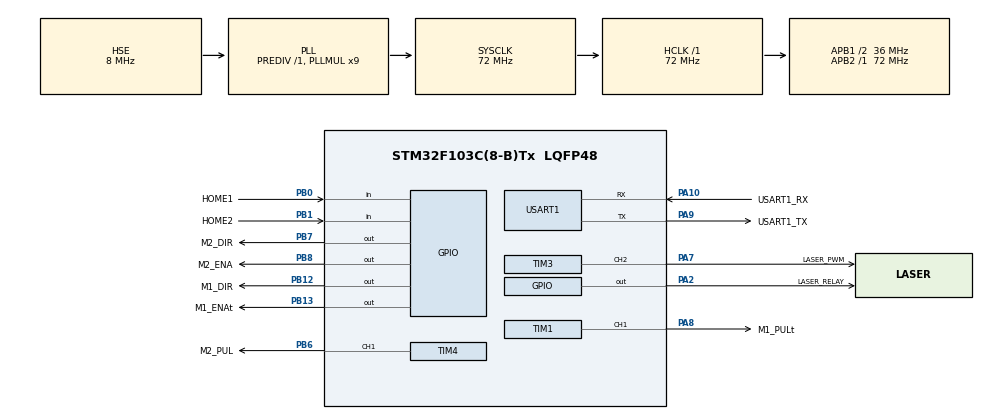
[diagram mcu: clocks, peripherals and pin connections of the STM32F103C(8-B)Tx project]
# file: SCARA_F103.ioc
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Dma.Request0=USART1_RX
Dma.Request1=USART1_TX
Dma.USART1_RX.0.Direction=DMA_PERIPH_TO_MEMORY
Dma.USART1_RX.0.Instance=DMA1_Channel5
Dma.USART1_RX.0.MemDataAlignment=DMA_MDATAALIGN_BYTE
Dma.USART1_RX.0.MemInc=DMA_MINC_ENABLE
Dma.USART1_RX.0.Mode=DMA_CIRCULAR
Dma.USART1_RX.0.PeriphDataAlignment=DMA_PDATAALIGN_BYTE
Dma.USART1_RX.0.PeriphInc=DMA_PINC_DISABLE
Dma.USART1_RX.0.Priority=DMA_PRIORITY_LOW
Dma.USART1_TX.1.Direction=DMA_MEMORY_TO_PERIPH
Dma.USART1_TX.1.Instance=DMA1_Channel4
Dma.USART1_TX.1.MemDataAlignment=DMA_MDATAALIGN_BYTE
Dma.USART1_TX.1.MemInc=DMA_MINC_ENABLE
Dma.USART1_TX.1.Mode=DMA_NORMAL
Dma.USART1_TX.1.PeriphDataAlignment=DMA_PDATAALIGN_BYTE
Dma.USART1_TX.1.PeriphInc=DMA_PINC_DISABLE
Dma.USART1_TX.1.Priority=DMA_PRIORITY_LOW
Mcu.Family=STM32F1
Mcu.Name=STM32F103C(8-B)Tx
Mcu.Package=LQFP48
NVIC.DMA1_Channel4_IRQn=true\:3\:0\:true\:false\:true\:false\:true\:true
NVIC.DMA1_Channel5_IRQn=true\:3\:0\:true\:false\:true\:false\:true\:true
NVIC.PriorityGroup=NVIC_PRIORITYGROUP_4
NVIC.TIM2_IRQn=true\:1\:0\:true\:false\:true\:true\:true\:true
NVIC.USART1_IRQn=true\:2\:0\:true\:false\:true\:false\:true\:true
PA10.GPIO_Label=USART1_RX
PA10.Mode=Asynchronous
PA10.Signal=USART1_RX
PA2.GPIO_Label=LASER_RELAY
PA2.GPIO_ModeDefaultOutputPP=GPIO_MODE_OUTPUT_PP
PA2.GPIO_PuPd=GPIO_NOPULL
PA2.GPIO_Speed=GPIO_SPEED_FREQ_LOW
PA2.PinState=GPIO_PIN_RESET
PA2.Signal=GPIO_Output
PA7.GPIO_Label=LASER_PWM
PA7.GPIO_ModeDefaultPP=GPIO_MODE_AF_PP
PA7.GPIO_Speed=GPIO_SPEED_FREQ_HIGH
PA7.Signal=S_TIM3_CH2
PA13.Mode=Serial_Wire
PA13.Signal=SYS_JTMS-SWDIO
PA14.Mode=Serial_Wire
PA14.Signal=SYS_JTCK-SWCLK
PA8.GPIO_Label=M1_PUL\t
PA8.GPIO_ModeDefaultPP=GPIO_MODE_AF_OD
PA8.GPIO_Speed=GPIO_SPEED_FREQ_HIGH
PA8.Signal=S_TIM1_CH1
PA9.GPIO_Label=USART1_TX
PA9.Mode=Asynchronous
PA9.Signal=USART1_TX
PB0.GPIO_Label=HOME1
PB0.GPIO_PuPd=GPIO_PULLUP
PB0.Signal=GPIO_Input
PB1.GPIO_Label=HOME2
PB1.GPIO_PuPd=GPIO_PULLUP
PB1.Signal=GPIO_Input
PB12.GPIO_Label=M1_DIR
PB12.GPIO_ModeDefaultOutputPP=GPIO_MODE_OUTPUT_OD
PB12.GPIO_PuPd=GPIO_NOPULL
PB12.GPIO_Speed=GPIO_SPEED_FREQ_HIGH
PB12.PinState=GPIO_PIN_SET
PB12.Signal=GPIO_Output
PB13.GPIO_Label=M1_ENA\t
PB13.GPIO_ModeDefaultOutputPP=GPIO_MODE_OUTPUT_OD
PB13.GPIO_PuPd=GPIO_NOPULL
PB13.GPIO_Speed=GPIO_SPEED_FREQ_HIGH
PB13.PinState=GPIO_PIN_SET
PB13.Signal=GPIO_Output
PB6.GPIO_Label=M2_PUL
PB6.GPIO_ModeDefaultPP=GPIO_MODE_AF_OD
PB6.GPIO_Speed=GPIO_SPEED_FREQ_HIGH
PB6.Signal=S_TIM4_CH1
PB7.GPIO_Label=M2_DIR
PB7.GPIO_ModeDefaultOutputPP=GPIO_MODE_OUTPUT_OD
PB7.GPIO_PuPd=GPIO_NOPULL
PB7.GPIO_Speed=GPIO_SPEED_FREQ_HIGH
PB7.PinState=GPIO_PIN_SET
PB7.Signal=GPIO_Output
PB8.GPIO_Label=M2_ENA
PB8.GPIO_ModeDefaultOutputPP=GPIO_MODE_OUTPUT_OD
PB8.GPIO_PuPd=GPIO_NOPULL
PB8.GPIO_Speed=GPIO_SPEED_FREQ_HIGH
PB8.PinState=GPIO_PIN_SET
PB8.Signal=GPIO_Output
PD0-OSC_IN.Mode=HSE-External-Oscillator
PD0-OSC_IN.Signal=RCC_OSC_IN
PD1-OSC_OUT.Mode=HSE-External-Oscillator
PD1-OSC_OUT.Signal=RCC_OSC_OUT
ProjectManager.HeapSize=0x200
ProjectManager.StackSize=0x400
ProjectManager.TargetToolchain=CMake
RCC.AHBFreq_Value=72000000
RCC.APB1CLKDivider=RCC_HCLK_DIV2
RCC.APB1Freq_Value=36000000
RCC.APB1TimFreq_Value=72000000
RCC.APB2Freq_Value=72000000
RCC.APB2TimFreq_Value=72000000
RCC.HCLKFreq_Value=72000000
RCC.PLLMUL=RCC_PLL_MUL9
RCC.PLLSourceVirtual=RCC_PLLSOURCE_HSE
RCC.SYSCLKFreq_VALUE=72000000
RCC.SYSCLKSource=RCC_SYSCLKSOURCE_PLLCLK
RCC.USBFreq_Value=72000000
SH.S_TIM1_CH1.0=TIM1_CH1,PWM Generation1 CH1
SH.S_TIM3_CH2.0=TIM3_CH2,PWM Generation2 CH2
SH.S_TIM4_CH1.0=TIM4_CH1,PWM Generation1 CH1
TIM1.Channel-PWM\ Generation1\ CH1=TIM_CHANNEL_1
TIM1.OCPolarity-PWM\ Generation1\ CH1=TIM_OCPOLARITY_LOW
TIM1.Period=5
TIM1.Prescaler=71
TIM1.Pulse-PWM\ Generation1\ CH1=3
TIM2.Period=99
TIM2.Prescaler=71
TIM3.Channel-PWM\ Generation2\ CH2=TIM_CHANNEL_2
TIM3.Period=999
TIM3.Prescaler=71
TIM3.Pulse-PWM\ Generation2\ CH2=0
TIM4.Channel-PWM\ Generation1\ CH1=TIM_CHANNEL_1
TIM4.OCPolarity-PWM\ Generation1\ CH1=TIM_OCPOLARITY_LOW
TIM4.Period=5
TIM4.Prescaler=71
TIM4.Pulse-PWM\ Generation1\ CH1=3
USART1.VirtualMode=VM_ASYNC
VP_TIM1_VS_ClockSourceINT.Mode=Internal
VP_TIM2_VS_ClockSourceINT.Mode=Internal
VP_TIM3_VS_ClockSourceINT.Mode=Internal
VP_TIM4_VS_ClockSourceINT.Mode=Internal
board=custom

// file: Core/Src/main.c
/* USER CODE BEGIN Header */
/**
  ******************************************************************************
  * @file           : main.c
  * @brief          : Main program body
  ******************************************************************************
  * @attention
  *
  * Copyright (c) 2026 STMicroelectronics.
  * All rights reserved.
  *
  * This software is licensed under terms that can be found in the LICENSE file
  * in the root directory of this software component.
  * If no LICENSE file comes with this software, it is provided AS-IS.
  *
  ******************************************************************************
  */
/* USER CODE END Header */
#include "main.h"
#include "dma.h"
#include "tim.h"
#include "usart.h"
#include "gpio.h"

/* USER CODE BEGIN Includes */
#include "app_main.h"
#include "laser_control.h"

/* USER CODE END Includes */

void SystemClock_Config(void);

int main(void)
{

  /* USER CODE BEGIN 1 */
  /* PA7 is a floating input after reset. Drive the laser PWM input to its
     configured off level before HAL or clock initialization can add delay. */
  LaserControl_EarlySafeOutput();

  /* USER CODE END 1 */

  /* MCU Configuration--------------------------------------------------------*/

  /* Reset of all peripherals, Initializes the Flash interface and the Systick. */
  HAL_Init();

  /* Configure the system clock */
  SystemClock_Config();

  /* Initialize all configured peripherals */
  MX_GPIO_Init();
  MX_DMA_Init();
  MX_TIM1_Init();
  MX_TIM4_Init();
  MX_USART1_UART_Init();
  MX_TIM2_Init();
  MX_TIM3_Init();
  /* USER CODE BEGIN 2 */
  App_Init();

  /* USER CODE END 2 */

  /* Infinite loop */
  while (1)
  {

    /* USER CODE BEGIN 3 */
    App_Loop();
  }
  /* USER CODE END 3 */
}

void SystemClock_Config(void)
{
  RCC_OscInitTypeDef RCC_OscInitStruct = {0};
  RCC_ClkInitTypeDef RCC_ClkInitStruct = {0};

  /** Initializes the RCC Oscillators according to the specified parameters
  * in the RCC_OscInitTypeDef structure.
  */
  RCC_OscInitStruct.OscillatorType = RCC_OSCILLATORTYPE_HSE;
  RCC_OscInitStruct.HSEState = RCC_HSE_ON;
  RCC_OscInitStruct.HSEPredivValue = RCC_HSE_PREDIV_DIV1;
  RCC_OscInitStruct.HSIState = RCC_HSI_ON;
  RCC_OscInitStruct.PLL.PLLState = RCC_PLL_ON;
  RCC_OscInitStruct.PLL.PLLSource = RCC_PLLSOURCE_HSE;
  RCC_OscInitStruct.PLL.PLLMUL = RCC_PLL_MUL9;
  if (HAL_RCC_OscConfig(&RCC_OscInitStruct) != HAL_OK)
  {
    Error_Handler();
  }

  /** Initializes the CPU, AHB and APB buses clocks
  */
  RCC_ClkInitStruct.ClockType = RCC_CLOCKTYPE_HCLK|RCC_CLOCKTYPE_SYSCLK
                              |RCC_CLOCKTYPE_PCLK1|RCC_CLOCKTYPE_PCLK2;
  RCC_ClkInitStruct.SYSCLKSource = RCC_SYSCLKSOURCE_PLLCLK;
  RCC_ClkInitStruct.AHBCLKDivider = RCC_SYSCLK_DIV1;
  RCC_ClkInitStruct.APB1CLKDivider = RCC_HCLK_DIV2;
  RCC_ClkInitStruct.APB2CLKDivider = RCC_HCLK_DIV1;

  if (HAL_RCC_ClockConfig(&RCC_ClkInitStruct, FLASH_LATENCY_2) != HAL_OK)
  {
    Error_Handler();
  }
}

void Error_Handler(void)
{
  /* USER CODE BEGIN Error_Handler_Debug */
  LaserControl_EarlySafeOutput();
  __disable_irq();
  while (1)
  {
  }
  /* USER CODE END Error_Handler_Debug */
}
